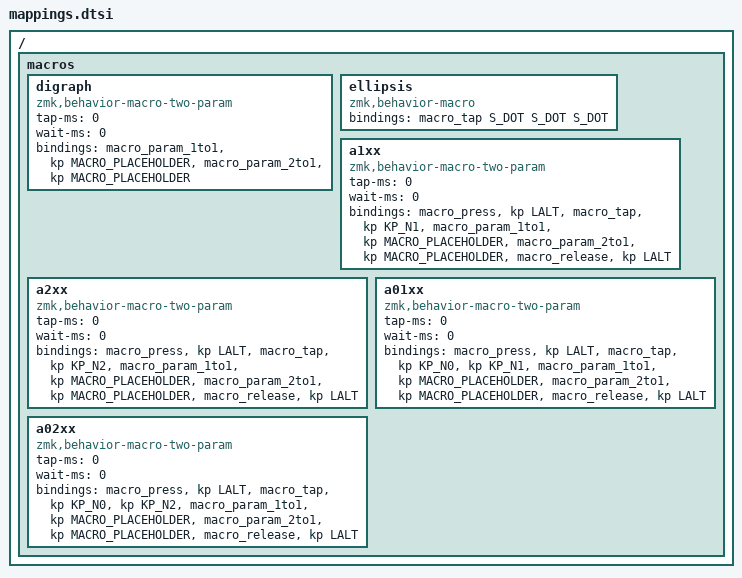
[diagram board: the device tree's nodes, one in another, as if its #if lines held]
#include <behaviors.dtsi>
#include <dt-bindings/zmk/keys.h>

// Define a dead layer key
// note: macro_pause_for_release might be useless
#define DEAD_KEY(name, key) name: name {       \
  compatible = "zmk,behavior-macro-one-param"; \
  #binding-cells = <1>;                        \
  tap-ms = <0>;                                \
  wait-ms = <0>;                               \
  bindings                                     \
    = <&macro_tap key>                         \
    , <&macro_pause_for_release>               \
    , <&macro_param_1to1>                      \
    , <&kp MACRO_PLACEHOLDER>                  \
    ;                                          \
};

// Define a shifted dead layer key
// note: macro_pause_for_release might be useless
#define DEAD_KEY_SHIFT(name, key) name: name { \
  compatible = "zmk,behavior-macro-one-param"; \
  #binding-cells = <1>;                        \
  tap-ms = <0>;                                \
  wait-ms = <0>;                               \
  bindings                                     \
    = <&macro_tap key>                         \
    , <&macro_pause_for_release>               \
    , <&macro_press &kp LSHIFT>                \
    , <&macro_param_1to1>                      \
    , <&kp MACRO_PLACEHOLDER>                  \
    , <&macro_release &kp LSHIFT>              \
    ;                                          \
};

// Define a two-level key (e.g. punctuation key)
#define TWO_LEVEL_KEY(name, base, shift) name: name { \
  compatible = "zmk,behavior-mod-morph";              \
  #binding-cells = <0>;                               \
  bindings = <base>, <shift>;                         \
  mods = <(MOD_LSFT|MOD_RSFT)>;                       \
};

/ {
  macros {
    digraph: digraph {
      compatible = "zmk,behavior-macro-two-param";
      #binding-cells = <2>;
      tap-ms = <0>;
      wait-ms = <0>;
      bindings
        = <&macro_param_1to1 &kp MACRO_PLACEHOLDER>
        , <&macro_param_2to1 &kp MACRO_PLACEHOLDER>
        ;
    };

    ellipsis: ellipsis {
      compatible = "zmk,behavior-macro";
      #binding-cells = <0>;
      bindings = <&macro_tap S_DOT S_DOT S_DOT>;
    };

    #ifdef ENABLE_ALT_KEYPAD
    a1xx: a1xx {
      compatible = "zmk,behavior-macro-two-param";
      #binding-cells = <2>;
      tap-ms = <0>;
      wait-ms = <0>;
      bindings
        = <&macro_press &kp LALT>
        , <&macro_tap &kp KP_N1>
        , <&macro_param_1to1 &kp MACRO_PLACEHOLDER>
        , <&macro_param_2to1 &kp MACRO_PLACEHOLDER>
        , <&macro_release &kp LALT>
        ;
    };
    a2xx: a2xx {
      compatible = "zmk,behavior-macro-two-param";
      #binding-cells = <2>;
      tap-ms = <0>;
      wait-ms = <0>;
      bindings
        = <&macro_press &kp LALT>
        , <&macro_tap &kp KP_N2>
        , <&macro_param_1to1 &kp MACRO_PLACEHOLDER>
        , <&macro_param_2to1 &kp MACRO_PLACEHOLDER>
        , <&macro_release &kp LALT>
        ;
    };
    a01xx: a01xx {
      compatible = "zmk,behavior-macro-two-param";
      #binding-cells = <2>;
      tap-ms = <0>;
      wait-ms = <0>;
      bindings
        = <&macro_press &kp LALT>
        , <&macro_tap &kp KP_N0 &kp KP_N1>
        , <&macro_param_1to1 &kp MACRO_PLACEHOLDER>
        , <&macro_param_2to1 &kp MACRO_PLACEHOLDER>
        , <&macro_release &kp LALT>
        ;
    };
    a02xx: a02xx {
      compatible = "zmk,behavior-macro-two-param";
      #binding-cells = <2>;
      tap-ms = <0>;
      wait-ms = <0>;
      bindings
        = <&macro_press &kp LALT>
        , <&macro_tap &kp KP_N0 &kp KP_N2>
        , <&macro_param_1to1 &kp MACRO_PLACEHOLDER>
        , <&macro_param_2to1 &kp MACRO_PLACEHOLDER>
        , <&macro_release &kp LALT>
        ;
    };
    #endif

  };
};
